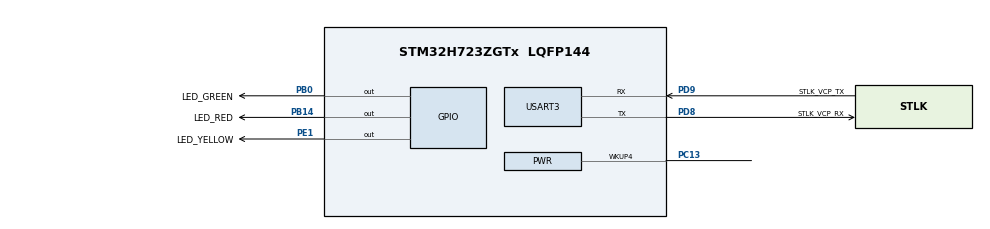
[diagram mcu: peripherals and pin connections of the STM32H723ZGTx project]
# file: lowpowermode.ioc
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Dma.Request0=USART3_RX
Dma.USART3_RX.0.Direction=DMA_PERIPH_TO_MEMORY
Dma.USART3_RX.0.EventEnable=DISABLE
Dma.USART3_RX.0.FIFOMode=DMA_FIFOMODE_DISABLE
Dma.USART3_RX.0.Instance=DMA1_Stream0
Dma.USART3_RX.0.MemDataAlignment=DMA_MDATAALIGN_BYTE
Dma.USART3_RX.0.MemInc=DMA_MINC_ENABLE
Dma.USART3_RX.0.Mode=DMA_CIRCULAR
Dma.USART3_RX.0.PeriphDataAlignment=DMA_PDATAALIGN_BYTE
Dma.USART3_RX.0.PeriphInc=DMA_PINC_DISABLE
Dma.USART3_RX.0.Polarity=HAL_DMAMUX_REQ_GEN_RISING
Dma.USART3_RX.0.Priority=DMA_PRIORITY_LOW
Dma.USART3_RX.0.RequestNumber=1
Dma.USART3_RX.0.SignalID=NONE
Dma.USART3_RX.0.SyncEnable=DISABLE
Dma.USART3_RX.0.SyncPolarity=HAL_DMAMUX_SYNC_NO_EVENT
Dma.USART3_RX.0.SyncRequestNumber=1
Dma.USART3_RX.0.SyncSignalID=NONE
Mcu.Family=STM32H7
Mcu.Name=STM32H723ZGTx
Mcu.Package=LQFP144
NVIC.DMA1_Stream0_IRQn=true\:0\:0\:false\:false\:true\:false\:true\:true
NVIC.PVD_AVD_IRQn=true\:0\:0\:false\:false\:true\:true\:true\:true
NVIC.PriorityGroup=NVIC_PRIORITYGROUP_4
NVIC.USART3_IRQn=true\:0\:0\:false\:false\:true\:true\:true\:true
PA13(JTMS/SWDIO).GPIO_Label=SWDIO
PA13(JTMS/SWDIO).Mode=Trace_Asynchronous_SW
PA13(JTMS/SWDIO).Signal=DEBUG_JTMS-SWDIO
PA14(JTCK/SWCLK).GPIO_Label=SWCLK
PA14(JTCK/SWCLK).Mode=Trace_Asynchronous_SW
PA14(JTCK/SWCLK).Signal=DEBUG_JTCK-SWCLK
PB0.GPIO_Label=LED_GREEN
PB0.Signal=GPIO_Output
PB14.GPIO_Label=LED_RED
PB14.Signal=GPIO_Output
PB3(JTDO/TRACESWO).GPIO_Label=SWO
PB3(JTDO/TRACESWO).Mode=Trace_Asynchronous_SW
PB3(JTDO/TRACESWO).Signal=DEBUG_JTDO-SWO
PC13.Mode=WakeUp4
PC13.Signal=PWR_WKUP4
PC14-OSC32_IN.Mode=LSE-External-Oscillator
PC14-OSC32_IN.Signal=RCC_OSC32_IN
PC15-OSC32_OUT.Mode=LSE-External-Oscillator
PC15-OSC32_OUT.Signal=RCC_OSC32_OUT
PD8.GPIO_Label=STLK_VCP_RX
PD8.Mode=Asynchronous
PD8.Signal=USART3_TX
PD9.GPIO_Label=STLK_VCP_TX
PD9.Mode=Asynchronous
PD9.Signal=USART3_RX
PE1.GPIO_Label=LED_YELLOW
PE1.Signal=GPIO_Output
PH0-OSC_IN.GPIO_Label=MCO
PH0-OSC_IN.Mode=HSE-External-Oscillator
PH0-OSC_IN.Signal=RCC_OSC_IN
PH1-OSC_OUT.Mode=HSE-External-Oscillator
PH1-OSC_OUT.Signal=RCC_OSC_OUT
ProjectManager.HeapSize=0x200
ProjectManager.StackSize=0x400
ProjectManager.TargetToolchain=STM32CubeIDE
RCC.ADCFreq_Value=96000000
RCC.APB1Freq_Value=137500000
RCC.APB2Freq_Value=137500000
RCC.APB3Freq_Value=137500000
RCC.APB4Freq_Value=137500000
RCC.CortexFreq_Value=550000000
RCC.D1PPRE=RCC_APB3_DIV2
RCC.D2PPRE1=RCC_APB1_DIV2
RCC.D2PPRE2=RCC_APB2_DIV2
RCC.D3PPRE=RCC_APB4_DIV2
RCC.DIVM1=4
RCC.DIVM2=1
RCC.DIVN1=275
RCC.DIVN2=24
RCC.DIVP1=1
RCC.DIVQ1=4
RCC.HCLKFreq_Value=275000000
RCC.HPRE=RCC_HCLK_DIV2
RCC.HSE_VALUE=8000000
RCC.PLLFRACN=0
RCC.PLLSourceVirtual=RCC_PLLSOURCE_HSE
RCC.RTCClockSelection=RCC_RTCCLKSOURCE_LSE
RCC.SYSCLKFreq_VALUE=550000000
RCC.SYSCLKSource=RCC_SYSCLKSOURCE_PLLCLK
RCC.USBCLockSelection=RCC_USBCLKSOURCE_HSI48
RCC.USBFreq_Value=48000000
USART3.VirtualMode-Asynchronous=VM_ASYNC
VP_MEMORYMAP_VS_MEMORYMAP.Mode=CurAppReg
VP_RTC_VS_RTC_Activate.Mode=RTC_Enabled
VP_RTC_VS_RTC_Calendar.Mode=RTC_Calendar
board=NUCLEO-H723ZG

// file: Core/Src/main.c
/* USER CODE BEGIN Header */
/**
  ******************************************************************************
  * @file           : main.c
  * @brief          : Main program body
  ******************************************************************************
  * @attention
  *
  * Copyright (c) 2024 STMicroelectronics.
  * All rights reserved.
  *
  * This software is licensed under terms that can be found in the LICENSE file
  * in the root directory of this software component.
  * If no LICENSE file comes with this software, it is provided AS-IS.
  *
  ******************************************************************************
  */
/* USER CODE END Header */
#include "main.h"
#include "dma.h"
#include "memorymap.h"
#include "rtc.h"
#include "usart.h"
#include "gpio.h"

/* USER CODE BEGIN Includes */
#include "sysInit.h"
#include "debugCLI.h"
#include "lowPowerMode.h"
/* USER CODE END Includes */

void SystemClock_Config(void);

int main(void)
{

  /* MCU Configuration--------------------------------------------------------*/

  /* Reset of all peripherals, Initializes the Flash interface and the Systick. */
  HAL_Init();

  /* Configure the system clock */
  SystemClock_Config();

  /* Initialize all configured peripherals */
  MX_GPIO_Init();
  MX_DMA_Init();
  MX_USART3_UART_Init();
  MX_RTC_Init();
  /* USER CODE BEGIN 2 */
  systemInit();
  /* USER CODE END 2 */

  /* Infinite loop */
  while (1)
  {

    /* USER CODE BEGIN 3 */
	  debugCLITask();

	  standbyModeTask();
  }
  /* USER CODE END 3 */
}

void SystemClock_Config(void)
{
  RCC_OscInitTypeDef RCC_OscInitStruct = {0};
  RCC_ClkInitTypeDef RCC_ClkInitStruct = {0};

  /** Supply configuration update enable
  */
  HAL_PWREx_ConfigSupply(PWR_LDO_SUPPLY);

  /** Configure the main internal regulator output voltage
  */
  __HAL_PWR_VOLTAGESCALING_CONFIG(PWR_REGULATOR_VOLTAGE_SCALE0);

  while(!__HAL_PWR_GET_FLAG(PWR_FLAG_VOSRDY)) {}

  /** Configure LSE Drive Capability
  */
  HAL_PWR_EnableBkUpAccess();
  __HAL_RCC_LSEDRIVE_CONFIG(RCC_LSEDRIVE_LOW);

  /** Initializes the RCC Oscillators according to the specified parameters
  * in the RCC_OscInitTypeDef structure.
  */
  RCC_OscInitStruct.OscillatorType = RCC_OSCILLATORTYPE_HSE|RCC_OSCILLATORTYPE_LSE;
  RCC_OscInitStruct.HSEState = RCC_HSE_ON;
  RCC_OscInitStruct.LSEState = RCC_LSE_ON;
  RCC_OscInitStruct.PLL.PLLState = RCC_PLL_ON;
  RCC_OscInitStruct.PLL.PLLSource = RCC_PLLSOURCE_HSE;
  RCC_OscInitStruct.PLL.PLLM = 4;
  RCC_OscInitStruct.PLL.PLLN = 275;
  RCC_OscInitStruct.PLL.PLLP = 1;
  RCC_OscInitStruct.PLL.PLLQ = 4;
  RCC_OscInitStruct.PLL.PLLR = 2;
  RCC_OscInitStruct.PLL.PLLRGE = RCC_PLL1VCIRANGE_1;
  RCC_OscInitStruct.PLL.PLLVCOSEL = RCC_PLL1VCOWIDE;
  RCC_OscInitStruct.PLL.PLLFRACN = 0;
  if (HAL_RCC_OscConfig(&RCC_OscInitStruct) != HAL_OK)
  {
    Error_Handler();
  }

  /** Initializes the CPU, AHB and APB buses clocks
  */
  RCC_ClkInitStruct.ClockType = RCC_CLOCKTYPE_HCLK|RCC_CLOCKTYPE_SYSCLK
                              |RCC_CLOCKTYPE_PCLK1|RCC_CLOCKTYPE_PCLK2
                              |RCC_CLOCKTYPE_D3PCLK1|RCC_CLOCKTYPE_D1PCLK1;
  RCC_ClkInitStruct.SYSCLKSource = RCC_SYSCLKSOURCE_PLLCLK;
  RCC_ClkInitStruct.SYSCLKDivider = RCC_SYSCLK_DIV1;
  RCC_ClkInitStruct.AHBCLKDivider = RCC_HCLK_DIV2;
  RCC_ClkInitStruct.APB3CLKDivider = RCC_APB3_DIV2;
  RCC_ClkInitStruct.APB1CLKDivider = RCC_APB1_DIV2;
  RCC_ClkInitStruct.APB2CLKDivider = RCC_APB2_DIV2;
  RCC_ClkInitStruct.APB4CLKDivider = RCC_APB4_DIV2;

  if (HAL_RCC_ClockConfig(&RCC_ClkInitStruct, FLASH_LATENCY_3) != HAL_OK)
  {
    Error_Handler();
  }
}

void Error_Handler(void)
{
  __disable_irq();
  while (1)
  {
  }
}
